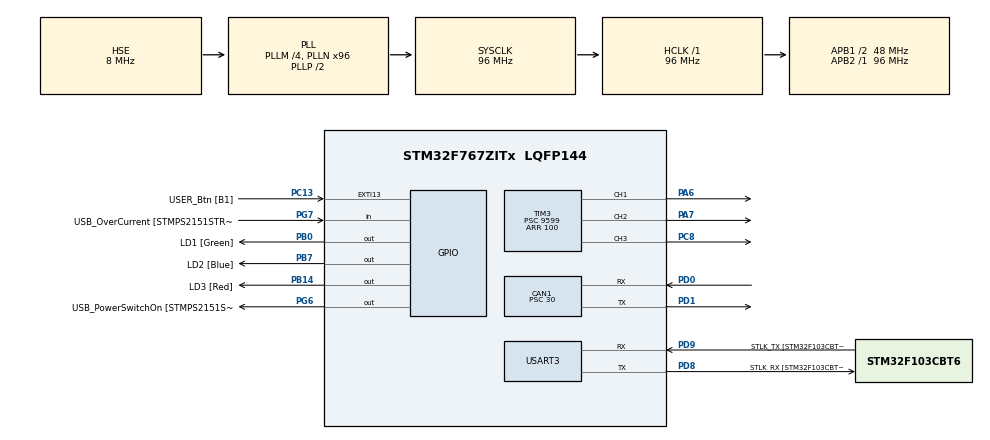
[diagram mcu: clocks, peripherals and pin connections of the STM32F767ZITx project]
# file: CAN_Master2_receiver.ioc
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CAN1.ABOM=DISABLE
CAN1.BS1=CAN_BS1_13TQ
CAN1.BS2=CAN_BS2_2TQ
CAN1.CalculateBaudRate=100000
CAN1.CalculateTimeBit=10000
CAN1.CalculateTimeQuantum=625.0
CAN1.Mode=CAN_MODE_NORMAL
CAN1.NART=DISABLE
CAN1.Prescaler=30
Mcu.Family=STM32F7
Mcu.Name=STM32F767ZITx
Mcu.Package=LQFP144
NVIC.CAN1_RX0_IRQn=true\:0\:0\:false\:false\:true\:true\:true\:true
NVIC.CAN1_RX1_IRQn=true\:0\:0\:false\:false\:true\:true\:true\:true
NVIC.PriorityGroup=NVIC_PRIORITYGROUP_4
NVIC.USART3_IRQn=true\:0\:0\:false\:false\:true\:true\:true\:true
PA13.GPIO_Label=TMS
PA13.Mode=Serial_Wire
PA13.Signal=SYS_JTMS-SWDIO
PA14.GPIO_Label=TCK
PA14.Mode=Serial_Wire
PA14.Signal=SYS_JTCK-SWCLK
PA6.Signal=S_TIM3_CH1
PA7.Signal=S_TIM3_CH2
PB0.GPIO_Label=LD1 [Green]
PB0.Signal=GPIO_Output
PB14.GPIO_Label=LD3 [Red]
PB14.Signal=GPIO_Output
PB7.GPIO_Label=LD2 [Blue]
PB7.Signal=GPIO_Output
PC13.GPIO_Label=USER_Btn [B1]
PC13.Signal=GPXTI13
PC14/OSC32_IN.Mode=LSE-External-Oscillator
PC14/OSC32_IN.Signal=RCC_OSC32_IN
PC15/OSC32_OUT.Mode=LSE-External-Oscillator
PC15/OSC32_OUT.Signal=RCC_OSC32_OUT
PC8.Signal=S_TIM3_CH3
PD0.GPIO_PuPd=GPIO_PULLUP
PD0.Mode=CAN_Activate
PD0.Signal=CAN1_RX
PD1.GPIO_PuPd=GPIO_PULLUP
PD1.Mode=CAN_Activate
PD1.Signal=CAN1_TX
PD8.GPIO_Label=STLK_RX [STM32F103CBT6_PA3]
PD8.Mode=Asynchronous
PD8.Signal=USART3_TX
PD9.GPIO_Label=STLK_TX [STM32F103CBT6_PA2]
PD9.Mode=Asynchronous
PD9.Signal=USART3_RX
PG6.GPIO_Label=USB_PowerSwitchOn [STMPS2151STR_EN]
PG6.Signal=GPIO_Output
PG7.GPIO_Label=USB_OverCurrent [STMPS2151STR_FAULT]
PG7.Signal=GPIO_Input
PH0/OSC_IN.GPIO_Label=MCO [STM32F103CBT6_PA8]
PH0/OSC_IN.Mode=HSE-External-Clock-Source
PH0/OSC_IN.Signal=RCC_OSC_IN
PH1/OSC_OUT.Mode=HSE-External-Clock-Source
PH1/OSC_OUT.Signal=RCC_OSC_OUT
ProjectManager.HeapSize=0x200
ProjectManager.StackSize=0x400
ProjectManager.TargetToolchain=STM32CubeIDE
RCC.48MHZClocksFreq_Value=24000000
RCC.AHBFreq_Value=96000000
RCC.APB1CLKDivider=RCC_HCLK_DIV2
RCC.APB1Freq_Value=48000000
RCC.APB1TimFreq_Value=96000000
RCC.APB2Freq_Value=96000000
RCC.APB2TimFreq_Value=96000000
RCC.CortexFreq_Value=96000000
RCC.HCLKFreq_Value=96000000
RCC.HSE_VALUE=8000000
RCC.HSI_VALUE=16000000
RCC.PLLM=4
RCC.PLLMUL=RCC_PLL_MUL9
RCC.PLLN=96
RCC.PLLQ=4
RCC.PLLSourceVirtual=RCC_PLLSOURCE_HSE
RCC.PRESCALERUSB=RCC_USBCLKSOURCE_PLL_DIV1_5
RCC.SYSCLKFreq_VALUE=96000000
RCC.SYSCLKSource=RCC_SYSCLKSOURCE_PLLCLK
RCC.SYSCLKSourceVirtual=RCC_SYSCLKSOURCE_PLLCLK
RCC.USBFreq_Value=48000000
RCC.VCOOutputFreq_Value=192000000
SH.S_TIM3_CH1.0=TIM3_CH1,PWM Generation1 CH1
SH.S_TIM3_CH2.0=TIM3_CH2,PWM Generation2 CH2
SH.S_TIM3_CH3.0=TIM3_CH3,PWM Generation3 CH3
TIM3.AutoReloadPreload=TIM_AUTORELOAD_PRELOAD_ENABLE
TIM3.Channel-PWM\ Generation1\ CH1=TIM_CHANNEL_1
TIM3.Channel-PWM\ Generation2\ CH2=TIM_CHANNEL_2
TIM3.Channel-PWM\ Generation3\ CH3=TIM_CHANNEL_3
TIM3.Period=100
TIM3.Prescaler=9599
TIM3.Pulse-PWM\ Generation1\ CH1=100
TIM3.Pulse-PWM\ Generation2\ CH2=100
TIM3.Pulse-PWM\ Generation3\ CH3=100
USART3.VirtualMode-Asynchronous=VM_ASYNC
VP_TIM3_VS_ClockSourceINT.Mode=Internal
board=NUCLEO-F767ZI

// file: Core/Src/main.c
/* USER CODE BEGIN Header */
/**
  ******************************************************************************
  * @file           : main.c
  * @brief          : Main program body
  ******************************************************************************
  * @attention
  *
  * Copyright (c) 2023 STMicroelectronics.
  * All rights reserved.
  *
  * This software is licensed under terms that can be found in the LICENSE file
  * in the root directory of this software component.
  * If no LICENSE file comes with this software, it is provided AS-IS.
  *
  ******************************************************************************
  */
/* USER CODE END Header */
#include "main.h"
#include "can.h"
#include "tim.h"
#include "usart.h"
#include "gpio.h"

/* USER CODE BEGIN Includes */

#include "sniffer.h"
#include "app_pwm.h"

/* USER CODE END Includes */

void SystemClock_Config(void);

int main(void)
{

  /* MCU Configuration--------------------------------------------------------*/

  /* Reset of all peripherals, Initializes the Flash interface and the Systick. */
  HAL_Init();

  /* Configure the system clock */
  SystemClock_Config();

  /* Initialize all configured peripherals */
  MX_GPIO_Init();
  MX_USART3_UART_Init();
  MX_CAN1_Init();
  MX_TIM3_Init();
  /* USER CODE BEGIN 2 */

  Sniffer_Init();
  AppPwm_Init();

  /* USER CODE END 2 */

  /* Infinite loop */
  while (1)
  {

  }
}

void SystemClock_Config(void)
{
  RCC_OscInitTypeDef RCC_OscInitStruct = {0};
  RCC_ClkInitTypeDef RCC_ClkInitStruct = {0};

  /** Configure LSE Drive Capability
  */
  HAL_PWR_EnableBkUpAccess();

  /** Configure the main internal regulator output voltage
  */
  __HAL_RCC_PWR_CLK_ENABLE();
  __HAL_PWR_VOLTAGESCALING_CONFIG(PWR_REGULATOR_VOLTAGE_SCALE3);

  /** Initializes the RCC Oscillators according to the specified parameters
  * in the RCC_OscInitTypeDef structure.
  */
  RCC_OscInitStruct.OscillatorType = RCC_OSCILLATORTYPE_HSE;
  RCC_OscInitStruct.HSEState = RCC_HSE_BYPASS;
  RCC_OscInitStruct.PLL.PLLState = RCC_PLL_ON;
  RCC_OscInitStruct.PLL.PLLSource = RCC_PLLSOURCE_HSE;
  RCC_OscInitStruct.PLL.PLLM = 4;
  RCC_OscInitStruct.PLL.PLLN = 96;
  RCC_OscInitStruct.PLL.PLLP = RCC_PLLP_DIV2;
  RCC_OscInitStruct.PLL.PLLQ = 4;
  RCC_OscInitStruct.PLL.PLLR = 2;
  if (HAL_RCC_OscConfig(&RCC_OscInitStruct) != HAL_OK)
  {
    Error_Handler();
  }

  /** Activate the Over-Drive mode
  */
  if (HAL_PWREx_EnableOverDrive() != HAL_OK)
  {
    Error_Handler();
  }

  /** Initializes the CPU, AHB and APB buses clocks
  */
  RCC_ClkInitStruct.ClockType = RCC_CLOCKTYPE_HCLK|RCC_CLOCKTYPE_SYSCLK
                              |RCC_CLOCKTYPE_PCLK1|RCC_CLOCKTYPE_PCLK2;
  RCC_ClkInitStruct.SYSCLKSource = RCC_SYSCLKSOURCE_PLLCLK;
  RCC_ClkInitStruct.AHBCLKDivider = RCC_SYSCLK_DIV1;
  RCC_ClkInitStruct.APB1CLKDivider = RCC_HCLK_DIV2;
  RCC_ClkInitStruct.APB2CLKDivider = RCC_HCLK_DIV1;

  if (HAL_RCC_ClockConfig(&RCC_ClkInitStruct, FLASH_LATENCY_3) != HAL_OK)
  {
    Error_Handler();
  }
}

/* USER CODE BEGIN 4 */

void HAL_CAN_RxFifo0MsgPendingCallback(CAN_HandleTypeDef *hcan)
{
	CAN_RxHeaderTypeDef rx_header;
	uint8_t rx_msg[8];

	HAL_CAN_GetRxMessage(&hcan1, CAN_RX_FIFO0, &rx_header, rx_msg);

	Sniffer_Transmit(rx_msg, rx_header.DLC, rx_header.StdId);
}

void HAL_CAN_RxFifo1MsgPendingCallback(CAN_HandleTypeDef *hcan)
{
	CAN_RxHeaderTypeDef rx_header;
	uint8_t rx_msg[8];

	HAL_CAN_GetRxMessage(&hcan1, CAN_RX_FIFO1, &rx_header, rx_msg);

	Sniffer_Transmit(rx_msg, rx_header.DLC, rx_header.StdId);
}

/* USER CODE END 4 */

void Error_Handler(void)
{
  __disable_irq();
  while (1)
  {
  }
}
